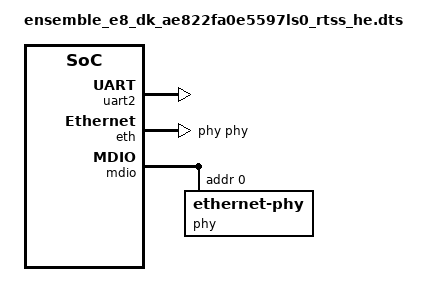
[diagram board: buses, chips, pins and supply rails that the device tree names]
/*
 * Copyright (c) 2025 Alif Semiconductor
 *
 * SPDX-License-Identifier: Apache-2.0
 */

/dts-v1/;

#include <alif/ensemble/ae822fa0e5597ls0.dtsi>
#include <alif/ensemble/ae822fa0e5597ls0_nvic_irq.dtsi>
#include <alif/ensemble/common/ensemble_rtss_he.dtsi>
#include "ensemble_e8_dk-pinctrl.dtsi"
#include "ensemble_e8_dk_common.dtsi"

/ {
	compatible = "alif,ensemble-e8-dk-ae822fa0e5597ls0-rtss-he";

	chosen {
		zephyr,flash = &mram;
		zephyr,sram = &dtcm;
		zephyr,console = &uart2;
		zephyr,shell-uart = &uart2;
	};
};

&uart2 {
	status = "okay";
	pinctrl-0 = <&uart2_default>;
	pinctrl-names = "default";
};

&eth {
	status = "okay";
	pinctrl-0 = <&eth_default>;
	pinctrl-names = "default";
	phy-handle = <&phy>;
	zephyr,random-mac-address;
};

&mdio {
	status = "okay";

	phy: ethernet-phy@0 {
		compatible = "ethernet-phy";
		reg = <0>;
		status = "okay";
	};
};
